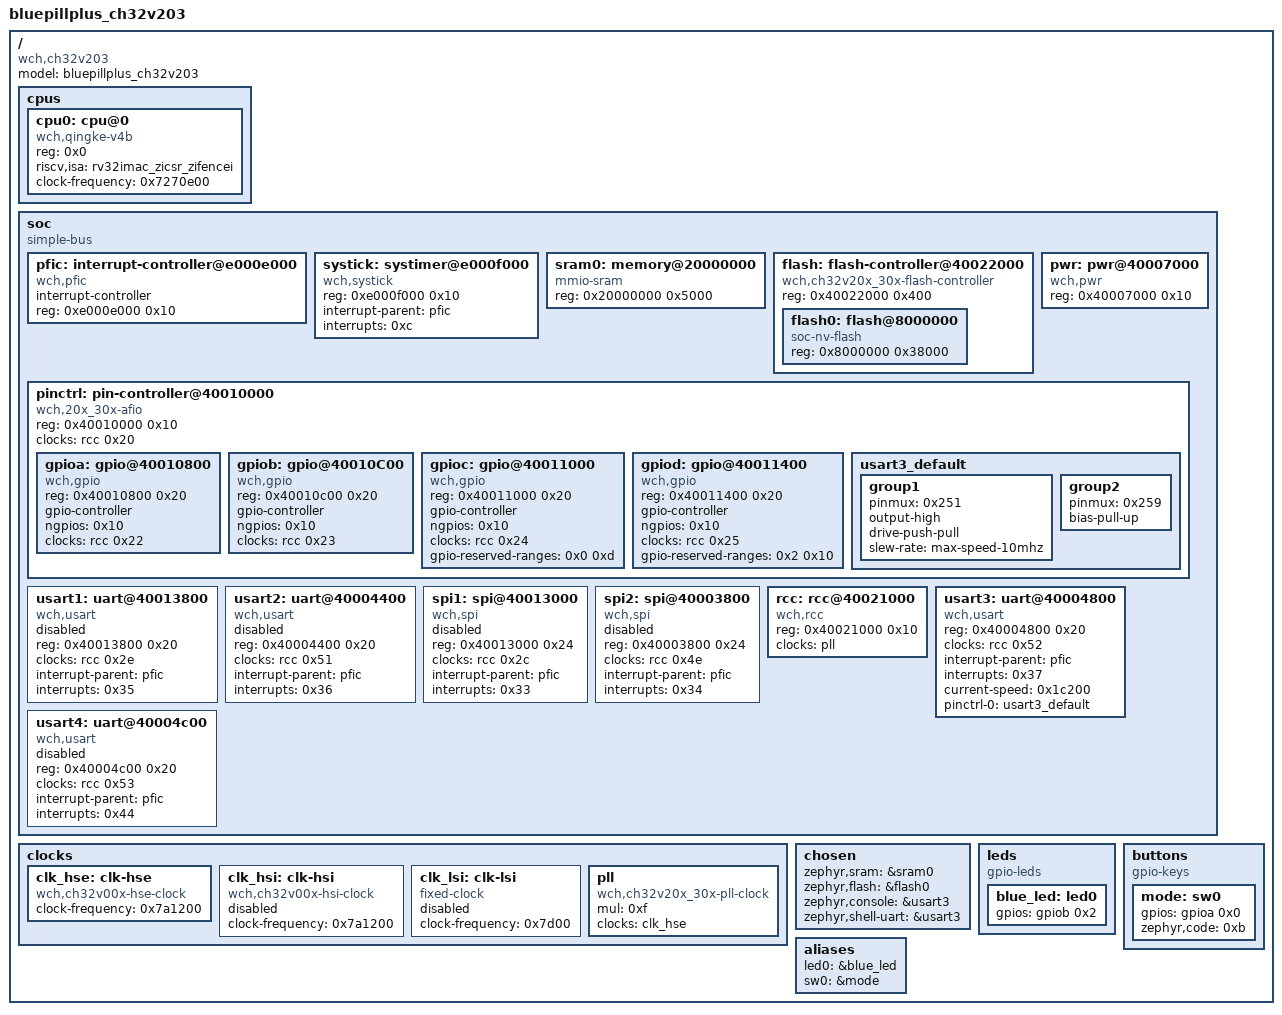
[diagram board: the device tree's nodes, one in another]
/dts-v1/;

/* node '/' defined in zephyr/dts/riscv/wch/qingke-v4b.dtsi:7 */
/ {
	#address-cells = < 0x1 >;        /* in zephyr/dts/riscv/wch/qingke-v4b.dtsi:8 */
	#size-cells = < 0x1 >;           /* in zephyr/dts/riscv/wch/qingke-v4b.dtsi:9 */
	model = "bluepillplus_ch32v203"; /* in zephyr/boards/weact/bluepillplus_ch32v203/bluepillplus_ch32v203.dts:14 */
	compatible = "wch,ch32v203";     /* in zephyr/boards/weact/bluepillplus_ch32v203/bluepillplus_ch32v203.dts:15 */

	/* node '/cpus' defined in zephyr/dts/riscv/wch/qingke-v4b.dtsi:11 */
	cpus {
		#address-cells = < 0x1 >; /* in zephyr/dts/riscv/wch/qingke-v4b.dtsi:12 */
		#size-cells = < 0x0 >;    /* in zephyr/dts/riscv/wch/qingke-v4b.dtsi:13 */

		/* node '/cpus/cpu@0' defined in zephyr/dts/riscv/wch/qingke-v4b.dtsi:15 */
		cpu0: cpu@0 {
			device_type = "cpu";                   /* in zephyr/dts/riscv/wch/qingke-v4b.dtsi:16 */
			compatible = "wch,qingke-v4b";         /* in zephyr/dts/riscv/wch/qingke-v4b.dtsi:17 */
			reg = < 0x0 >;                         /* in zephyr/dts/riscv/wch/qingke-v4b.dtsi:18 */
			riscv,isa = "rv32imac_zicsr_zifencei"; /* in zephyr/dts/riscv/wch/qingke-v4b.dtsi:19 */
			clock-frequency = < 0x7270e00 >;       /* in zephyr/dts/riscv/wch/ch32v203/ch32v203.dtsi:160 */
		};
	};

	/* node '/soc' defined in zephyr/dts/riscv/wch/qingke-v4b.dtsi:23 */
	soc {
		#address-cells = < 0x1 >;  /* in zephyr/dts/riscv/wch/qingke-v4b.dtsi:24 */
		#size-cells = < 0x1 >;     /* in zephyr/dts/riscv/wch/qingke-v4b.dtsi:25 */
		compatible = "simple-bus"; /* in zephyr/dts/riscv/wch/qingke-v4b.dtsi:26 */
		ranges;                    /* in zephyr/dts/riscv/wch/qingke-v4b.dtsi:27 */

		/* node '/soc/interrupt-controller@e000e000' defined in zephyr/dts/riscv/wch/qingke-v4b.dtsi:29 */
		pfic: interrupt-controller@e000e000 {
			compatible = "wch,pfic";    /* in zephyr/dts/riscv/wch/qingke-v4b.dtsi:30 */
			#address-cells = < 0x0 >;   /* in zephyr/dts/riscv/wch/qingke-v4b.dtsi:31 */
			#interrupt-cells = < 0x1 >; /* in zephyr/dts/riscv/wch/qingke-v4b.dtsi:32 */
			interrupt-controller;       /* in zephyr/dts/riscv/wch/qingke-v4b.dtsi:33 */
			reg = < 0xe000e000 0x10 >;  /* in zephyr/dts/riscv/wch/qingke-v4b.dtsi:34 */
			status = "okay";            /* in zephyr/dts/riscv/wch/qingke-v4b.dtsi:35 */
			phandle = < 0x1 >;          /* in zephyr/dts/riscv/wch/qingke-v4b.dtsi:42 */
		};

		/* node '/soc/systimer@e000f000' defined in zephyr/dts/riscv/wch/qingke-v4b.dtsi:38 */
		systick: systimer@e000f000 {
			compatible = "wch,systick";   /* in zephyr/dts/riscv/wch/qingke-v4b.dtsi:39 */
			reg = < 0xe000f000 0x10 >;    /* in zephyr/dts/riscv/wch/qingke-v4b.dtsi:40 */
			status = "okay";              /* in zephyr/dts/riscv/wch/qingke-v4b.dtsi:41 */
			interrupt-parent = < &pfic >; /* in zephyr/dts/riscv/wch/qingke-v4b.dtsi:42 */
			interrupts = < 0xc >;         /* in zephyr/dts/riscv/wch/qingke-v4b.dtsi:43 */
		};

		/* node '/soc/memory@20000000' defined in zephyr/dts/riscv/wch/ch32v203/ch32v203.dtsi:46 */
		sram0: memory@20000000 {
			compatible = "mmio-sram";    /* in zephyr/dts/riscv/wch/ch32v203/ch32v203.dtsi:47 */
			reg = < 0x20000000 0x5000 >; /* in zephyr/dts/riscv/wch/ch32v203/ch32v203c8t.dtsi:18 */
		};

		/* node '/soc/flash-controller@40022000' defined in zephyr/dts/riscv/wch/ch32v203/ch32v203.dtsi:50 */
		flash: flash-controller@40022000 {
			compatible = "wch,ch32v20x_30x-flash-controller"; /* in zephyr/dts/riscv/wch/ch32v203/ch32v203.dtsi:51 */
			reg = < 0x40022000 0x400 >;                       /* in zephyr/dts/riscv/wch/ch32v203/ch32v203.dtsi:52 */
			#address-cells = < 0x1 >;                         /* in zephyr/dts/riscv/wch/ch32v203/ch32v203.dtsi:53 */
			#size-cells = < 0x1 >;                            /* in zephyr/dts/riscv/wch/ch32v203/ch32v203.dtsi:54 */

			/* node '/soc/flash-controller@40022000/flash@8000000' defined in zephyr/dts/riscv/wch/ch32v203/ch32v203.dtsi:56 */
			flash0: flash@8000000 {
				compatible = "soc-nv-flash"; /* in zephyr/dts/riscv/wch/ch32v203/ch32v203.dtsi:57 */
				reg = < 0x8000000 0x38000 >; /* in zephyr/dts/riscv/wch/ch32v203/ch32v203.dtsi:58 */
			};
		};

		/* node '/soc/pwr@40007000' defined in zephyr/dts/riscv/wch/ch32v203/ch32v203.dtsi:62 */
		pwr: pwr@40007000 {
			compatible = "wch,pwr";    /* in zephyr/dts/riscv/wch/ch32v203/ch32v203.dtsi:63 */
			reg = < 0x40007000 0x10 >; /* in zephyr/dts/riscv/wch/ch32v203/ch32v203.dtsi:64 */
		};

		/* node '/soc/pin-controller@40010000' defined in zephyr/dts/riscv/wch/ch32v203/ch32v203.dtsi:67 */
		pinctrl: pin-controller@40010000 {
			compatible = "wch,20x_30x-afio"; /* in zephyr/dts/riscv/wch/ch32v203/ch32v203.dtsi:68 */
			reg = < 0x40010000 0x10 >;       /* in zephyr/dts/riscv/wch/ch32v203/ch32v203.dtsi:69 */
			#address-cells = < 0x1 >;        /* in zephyr/dts/riscv/wch/ch32v203/ch32v203.dtsi:70 */
			#size-cells = < 0x1 >;           /* in zephyr/dts/riscv/wch/ch32v203/ch32v203.dtsi:71 */
			clocks = < &rcc 0x20 >;          /* in zephyr/dts/riscv/wch/ch32v203/ch32v203.dtsi:72 */

			/* node '/soc/pin-controller@40010000/gpio@40010800' defined in zephyr/dts/riscv/wch/ch32v203/ch32v203.dtsi:74 */
			gpioa: gpio@40010800 {
				compatible = "wch,gpio";   /* in zephyr/dts/riscv/wch/ch32v203/ch32v203.dtsi:75 */
				reg = < 0x40010800 0x20 >; /* in zephyr/dts/riscv/wch/ch32v203/ch32v203.dtsi:76 */
				gpio-controller;           /* in zephyr/dts/riscv/wch/ch32v203/ch32v203.dtsi:77 */
				#gpio-cells = < 0x2 >;     /* in zephyr/dts/riscv/wch/ch32v203/ch32v203.dtsi:78 */
				ngpios = < 0x10 >;         /* in zephyr/dts/riscv/wch/ch32v203/ch32v203.dtsi:79 */
				clocks = < &rcc 0x22 >;    /* in zephyr/dts/riscv/wch/ch32v203/ch32v203.dtsi:80 */
				status = "okay";           /* in zephyr/boards/weact/bluepillplus_ch32v203/bluepillplus_ch32v203.dts:63 */
				phandle = < 0x7 >;         /* in zephyr/boards/weact/bluepillplus_ch32v203/bluepillplus_ch32v203.dts:37 */
			};

			/* node '/soc/pin-controller@40010000/gpio@40010C00' defined in zephyr/dts/riscv/wch/ch32v203/ch32v203.dtsi:83 */
			gpiob: gpio@40010C00 {
				compatible = "wch,gpio";   /* in zephyr/dts/riscv/wch/ch32v203/ch32v203.dtsi:84 */
				reg = < 0x40010c00 0x20 >; /* in zephyr/dts/riscv/wch/ch32v203/ch32v203.dtsi:85 */
				gpio-controller;           /* in zephyr/dts/riscv/wch/ch32v203/ch32v203.dtsi:86 */
				#gpio-cells = < 0x2 >;     /* in zephyr/dts/riscv/wch/ch32v203/ch32v203.dtsi:87 */
				ngpios = < 0x10 >;         /* in zephyr/dts/riscv/wch/ch32v203/ch32v203.dtsi:88 */
				clocks = < &rcc 0x23 >;    /* in zephyr/dts/riscv/wch/ch32v203/ch32v203.dtsi:89 */
				status = "okay";           /* in zephyr/boards/weact/bluepillplus_ch32v203/bluepillplus_ch32v203.dts:67 */
				phandle = < 0x6 >;         /* in zephyr/boards/weact/bluepillplus_ch32v203/bluepillplus_ch32v203.dts:29 */
			};

			/* node '/soc/pin-controller@40010000/gpio@40011000' defined in zephyr/dts/riscv/wch/ch32v203/ch32v203.dtsi:92 */
			gpioc: gpio@40011000 {
				compatible = "wch,gpio";            /* in zephyr/dts/riscv/wch/ch32v203/ch32v203.dtsi:93 */
				reg = < 0x40011000 0x20 >;          /* in zephyr/dts/riscv/wch/ch32v203/ch32v203.dtsi:94 */
				gpio-controller;                    /* in zephyr/dts/riscv/wch/ch32v203/ch32v203.dtsi:95 */
				#gpio-cells = < 0x2 >;              /* in zephyr/dts/riscv/wch/ch32v203/ch32v203.dtsi:96 */
				ngpios = < 0x10 >;                  /* in zephyr/dts/riscv/wch/ch32v203/ch32v203.dtsi:97 */
				clocks = < &rcc 0x24 >;             /* in zephyr/dts/riscv/wch/ch32v203/ch32v203.dtsi:98 */
				gpio-reserved-ranges = < 0x0 0xd >; /* in zephyr/dts/riscv/wch/ch32v203/ch32v203c8t.dtsi:10 */
				status = "okay";                    /* in zephyr/boards/weact/bluepillplus_ch32v203/bluepillplus_ch32v203.dts:71 */
			};

			/* node '/soc/pin-controller@40010000/gpio@40011400' defined in zephyr/dts/riscv/wch/ch32v203/ch32v203.dtsi:101 */
			gpiod: gpio@40011400 {
				compatible = "wch,gpio";             /* in zephyr/dts/riscv/wch/ch32v203/ch32v203.dtsi:102 */
				reg = < 0x40011400 0x20 >;           /* in zephyr/dts/riscv/wch/ch32v203/ch32v203.dtsi:103 */
				gpio-controller;                     /* in zephyr/dts/riscv/wch/ch32v203/ch32v203.dtsi:104 */
				#gpio-cells = < 0x2 >;               /* in zephyr/dts/riscv/wch/ch32v203/ch32v203.dtsi:105 */
				ngpios = < 0x10 >;                   /* in zephyr/dts/riscv/wch/ch32v203/ch32v203.dtsi:106 */
				clocks = < &rcc 0x25 >;              /* in zephyr/dts/riscv/wch/ch32v203/ch32v203.dtsi:107 */
				gpio-reserved-ranges = < 0x2 0x10 >; /* in zephyr/dts/riscv/wch/ch32v203/ch32v203c8t.dtsi:14 */
			};

			/* node '/soc/pin-controller@40010000/usart3_default' defined in zephyr/boards/weact/bluepillplus_ch32v203/bluepillplus_ch32v203-pinctrl.dtsi:9 */
			usart3_default: usart3_default {
				phandle = < 0x4 >; /* in zephyr/boards/weact/bluepillplus_ch32v203/bluepillplus_ch32v203.dts:77 */

				/* node '/soc/pin-controller@40010000/usart3_default/group1' defined in zephyr/boards/weact/bluepillplus_ch32v203/bluepillplus_ch32v203-pinctrl.dtsi:10 */
				group1 {
					pinmux = < 0x251 >;            /* in zephyr/boards/weact/bluepillplus_ch32v203/bluepillplus_ch32v203-pinctrl.dtsi:11 */
					output-high;                   /* in zephyr/boards/weact/bluepillplus_ch32v203/bluepillplus_ch32v203-pinctrl.dtsi:12 */
					drive-push-pull;               /* in zephyr/boards/weact/bluepillplus_ch32v203/bluepillplus_ch32v203-pinctrl.dtsi:13 */
					slew-rate = "max-speed-10mhz"; /* in zephyr/boards/weact/bluepillplus_ch32v203/bluepillplus_ch32v203-pinctrl.dtsi:14 */
				};

				/* node '/soc/pin-controller@40010000/usart3_default/group2' defined in zephyr/boards/weact/bluepillplus_ch32v203/bluepillplus_ch32v203-pinctrl.dtsi:17 */
				group2 {
					pinmux = < 0x259 >; /* in zephyr/boards/weact/bluepillplus_ch32v203/bluepillplus_ch32v203-pinctrl.dtsi:18 */
					bias-pull-up;       /* in zephyr/boards/weact/bluepillplus_ch32v203/bluepillplus_ch32v203-pinctrl.dtsi:19 */
				};
			};
		};

		/* node '/soc/uart@40013800' defined in zephyr/dts/riscv/wch/ch32v203/ch32v203.dtsi:111 */
		usart1: uart@40013800 {
			compatible = "wch,usart";     /* in zephyr/dts/riscv/wch/ch32v203/ch32v203.dtsi:112 */
			reg = < 0x40013800 0x20 >;    /* in zephyr/dts/riscv/wch/ch32v203/ch32v203.dtsi:113 */
			clocks = < &rcc 0x2e >;       /* in zephyr/dts/riscv/wch/ch32v203/ch32v203.dtsi:114 */
			interrupt-parent = < &pfic >; /* in zephyr/dts/riscv/wch/ch32v203/ch32v203.dtsi:115 */
			interrupts = < 0x35 >;        /* in zephyr/dts/riscv/wch/ch32v203/ch32v203.dtsi:116 */
			status = "disabled";          /* in zephyr/dts/riscv/wch/ch32v203/ch32v203.dtsi:117 */
		};

		/* node '/soc/uart@40004400' defined in zephyr/dts/riscv/wch/ch32v203/ch32v203.dtsi:120 */
		usart2: uart@40004400 {
			compatible = "wch,usart";     /* in zephyr/dts/riscv/wch/ch32v203/ch32v203.dtsi:121 */
			reg = < 0x40004400 0x20 >;    /* in zephyr/dts/riscv/wch/ch32v203/ch32v203.dtsi:122 */
			clocks = < &rcc 0x51 >;       /* in zephyr/dts/riscv/wch/ch32v203/ch32v203.dtsi:123 */
			interrupt-parent = < &pfic >; /* in zephyr/dts/riscv/wch/ch32v203/ch32v203.dtsi:124 */
			interrupts = < 0x36 >;        /* in zephyr/dts/riscv/wch/ch32v203/ch32v203.dtsi:125 */
			status = "disabled";          /* in zephyr/dts/riscv/wch/ch32v203/ch32v203.dtsi:126 */
		};

		/* node '/soc/spi@40013000' defined in zephyr/dts/riscv/wch/ch32v203/ch32v203.dtsi:129 */
		spi1: spi@40013000 {
			compatible = "wch,spi";       /* in zephyr/dts/riscv/wch/ch32v203/ch32v203.dtsi:130 */
			reg = < 0x40013000 0x24 >;    /* in zephyr/dts/riscv/wch/ch32v203/ch32v203.dtsi:131 */
			clocks = < &rcc 0x2c >;       /* in zephyr/dts/riscv/wch/ch32v203/ch32v203.dtsi:132 */
			interrupt-parent = < &pfic >; /* in zephyr/dts/riscv/wch/ch32v203/ch32v203.dtsi:133 */
			interrupts = < 0x33 >;        /* in zephyr/dts/riscv/wch/ch32v203/ch32v203.dtsi:134 */
			status = "disabled";          /* in zephyr/dts/riscv/wch/ch32v203/ch32v203.dtsi:135 */
			#address-cells = < 0x1 >;     /* in zephyr/dts/riscv/wch/ch32v203/ch32v203.dtsi:136 */
			#size-cells = < 0x0 >;        /* in zephyr/dts/riscv/wch/ch32v203/ch32v203.dtsi:137 */
		};

		/* node '/soc/spi@40003800' defined in zephyr/dts/riscv/wch/ch32v203/ch32v203.dtsi:140 */
		spi2: spi@40003800 {
			compatible = "wch,spi";       /* in zephyr/dts/riscv/wch/ch32v203/ch32v203.dtsi:141 */
			reg = < 0x40003800 0x24 >;    /* in zephyr/dts/riscv/wch/ch32v203/ch32v203.dtsi:142 */
			clocks = < &rcc 0x4e >;       /* in zephyr/dts/riscv/wch/ch32v203/ch32v203.dtsi:143 */
			interrupt-parent = < &pfic >; /* in zephyr/dts/riscv/wch/ch32v203/ch32v203.dtsi:144 */
			interrupts = < 0x34 >;        /* in zephyr/dts/riscv/wch/ch32v203/ch32v203.dtsi:145 */
			status = "disabled";          /* in zephyr/dts/riscv/wch/ch32v203/ch32v203.dtsi:146 */
			#address-cells = < 0x1 >;     /* in zephyr/dts/riscv/wch/ch32v203/ch32v203.dtsi:147 */
			#size-cells = < 0x0 >;        /* in zephyr/dts/riscv/wch/ch32v203/ch32v203.dtsi:148 */
		};

		/* node '/soc/rcc@40021000' defined in zephyr/dts/riscv/wch/ch32v203/ch32v203.dtsi:151 */
		rcc: rcc@40021000 {
			compatible = "wch,rcc";    /* in zephyr/dts/riscv/wch/ch32v203/ch32v203.dtsi:152 */
			reg = < 0x40021000 0x10 >; /* in zephyr/dts/riscv/wch/ch32v203/ch32v203.dtsi:153 */
			#clock-cells = < 0x1 >;    /* in zephyr/dts/riscv/wch/ch32v203/ch32v203.dtsi:154 */
			clocks = < &pll >;         /* in zephyr/boards/weact/bluepillplus_ch32v203/bluepillplus_ch32v203.dts:59 */
			phandle = < 0x2 >;         /* in zephyr/dts/riscv/wch/ch32v203/ch32v203.dtsi:72 */
		};

		/* node '/soc/uart@40004800' defined in zephyr/dts/riscv/wch/ch32v203/ch32v203c8t.dtsi:23 */
		usart3: uart@40004800 {
			compatible = "wch,usart";        /* in zephyr/dts/riscv/wch/ch32v203/ch32v203c8t.dtsi:24 */
			reg = < 0x40004800 0x20 >;       /* in zephyr/dts/riscv/wch/ch32v203/ch32v203c8t.dtsi:25 */
			clocks = < &rcc 0x52 >;          /* in zephyr/dts/riscv/wch/ch32v203/ch32v203c8t.dtsi:26 */
			interrupt-parent = < &pfic >;    /* in zephyr/dts/riscv/wch/ch32v203/ch32v203c8t.dtsi:27 */
			interrupts = < 0x37 >;           /* in zephyr/dts/riscv/wch/ch32v203/ch32v203c8t.dtsi:28 */
			status = "okay";                 /* in zephyr/boards/weact/bluepillplus_ch32v203/bluepillplus_ch32v203.dts:75 */
			current-speed = < 0x1c200 >;     /* in zephyr/boards/weact/bluepillplus_ch32v203/bluepillplus_ch32v203.dts:76 */
			pinctrl-0 = < &usart3_default >; /* in zephyr/boards/weact/bluepillplus_ch32v203/bluepillplus_ch32v203.dts:77 */
			pinctrl-names = "default";       /* in zephyr/boards/weact/bluepillplus_ch32v203/bluepillplus_ch32v203.dts:78 */
		};

		/* node '/soc/uart@40004c00' defined in zephyr/dts/riscv/wch/ch32v203/ch32v203c8t.dtsi:32 */
		usart4: uart@40004c00 {
			compatible = "wch,usart";     /* in zephyr/dts/riscv/wch/ch32v203/ch32v203c8t.dtsi:33 */
			reg = < 0x40004c00 0x20 >;    /* in zephyr/dts/riscv/wch/ch32v203/ch32v203c8t.dtsi:34 */
			clocks = < &rcc 0x53 >;       /* in zephyr/dts/riscv/wch/ch32v203/ch32v203c8t.dtsi:35 */
			interrupt-parent = < &pfic >; /* in zephyr/dts/riscv/wch/ch32v203/ch32v203c8t.dtsi:36 */
			interrupts = < 0x44 >;        /* in zephyr/dts/riscv/wch/ch32v203/ch32v203c8t.dtsi:37 */
			status = "disabled";          /* in zephyr/dts/riscv/wch/ch32v203/ch32v203c8t.dtsi:38 */
		};
	};

	/* node '/clocks' defined in zephyr/dts/riscv/wch/ch32v203/ch32v203.dtsi:15 */
	clocks {

		/* node '/clocks/clk-hse' defined in zephyr/dts/riscv/wch/ch32v203/ch32v203.dtsi:16 */
		clk_hse: clk-hse {
			#clock-cells = < 0x0 >;                /* in zephyr/dts/riscv/wch/ch32v203/ch32v203.dtsi:17 */
			compatible = "wch,ch32v00x-hse-clock"; /* in zephyr/dts/riscv/wch/ch32v203/ch32v203.dtsi:18 */
			clock-frequency = < 0x7a1200 >;        /* in zephyr/boards/weact/bluepillplus_ch32v203/bluepillplus_ch32v203.dts:49 */
			status = "okay";                       /* in zephyr/boards/weact/bluepillplus_ch32v203/bluepillplus_ch32v203.dts:50 */
			phandle = < 0x5 >;                     /* in zephyr/boards/weact/bluepillplus_ch32v203/bluepillplus_ch32v203.dts:54 */
		};

		/* node '/clocks/clk-hsi' defined in zephyr/dts/riscv/wch/ch32v203/ch32v203.dtsi:23 */
		clk_hsi: clk-hsi {
			#clock-cells = < 0x0 >;                /* in zephyr/dts/riscv/wch/ch32v203/ch32v203.dtsi:24 */
			compatible = "wch,ch32v00x-hsi-clock"; /* in zephyr/dts/riscv/wch/ch32v203/ch32v203.dtsi:25 */
			clock-frequency = < 0x7a1200 >;        /* in zephyr/dts/riscv/wch/ch32v203/ch32v203.dtsi:26 */
			status = "disabled";                   /* in zephyr/dts/riscv/wch/ch32v203/ch32v203.dtsi:27 */
		};

		/* node '/clocks/clk-lsi' defined in zephyr/dts/riscv/wch/ch32v203/ch32v203.dtsi:30 */
		clk_lsi: clk-lsi {
			#clock-cells = < 0x0 >;       /* in zephyr/dts/riscv/wch/ch32v203/ch32v203.dtsi:31 */
			compatible = "fixed-clock";   /* in zephyr/dts/riscv/wch/ch32v203/ch32v203.dtsi:32 */
			clock-frequency = < 0x7d00 >; /* in zephyr/dts/riscv/wch/ch32v203/ch32v203.dtsi:33 */
			status = "disabled";          /* in zephyr/dts/riscv/wch/ch32v203/ch32v203.dtsi:34 */
		};

		/* node '/clocks/pll' defined in zephyr/dts/riscv/wch/ch32v203/ch32v203.dtsi:37 */
		pll: pll {
			#clock-cells = < 0x0 >;                    /* in zephyr/dts/riscv/wch/ch32v203/ch32v203.dtsi:38 */
			compatible = "wch,ch32v20x_30x-pll-clock"; /* in zephyr/dts/riscv/wch/ch32v203/ch32v203.dtsi:39 */
			mul = < 0xf >;                             /* in zephyr/dts/riscv/wch/ch32v203/ch32v203.dtsi:40 */
			clocks = < &clk_hse >;                     /* in zephyr/boards/weact/bluepillplus_ch32v203/bluepillplus_ch32v203.dts:54 */
			status = "okay";                           /* in zephyr/boards/weact/bluepillplus_ch32v203/bluepillplus_ch32v203.dts:55 */
			phandle = < 0x3 >;                         /* in zephyr/boards/weact/bluepillplus_ch32v203/bluepillplus_ch32v203.dts:59 */
		};
	};

	/* node '/chosen' defined in zephyr/boards/weact/bluepillplus_ch32v203/bluepillplus_ch32v203.dts:17 */
	chosen {
		zephyr,sram = &sram0;        /* in zephyr/boards/weact/bluepillplus_ch32v203/bluepillplus_ch32v203.dts:18 */
		zephyr,flash = &flash0;      /* in zephyr/boards/weact/bluepillplus_ch32v203/bluepillplus_ch32v203.dts:19 */
		zephyr,console = &usart3;    /* in zephyr/boards/weact/bluepillplus_ch32v203/bluepillplus_ch32v203.dts:20 */
		zephyr,shell-uart = &usart3; /* in zephyr/boards/weact/bluepillplus_ch32v203/bluepillplus_ch32v203.dts:21 */
	};

	/* node '/leds' defined in zephyr/boards/weact/bluepillplus_ch32v203/bluepillplus_ch32v203.dts:24 */
	leds {
		compatible = "gpio-leds"; /* in zephyr/boards/weact/bluepillplus_ch32v203/bluepillplus_ch32v203.dts:25 */
		status = "okay";          /* in zephyr/boards/weact/bluepillplus_ch32v203/bluepillplus_ch32v203.dts:26 */

		/* node '/leds/led0' defined in zephyr/boards/weact/bluepillplus_ch32v203/bluepillplus_ch32v203.dts:28 */
		blue_led: led0 {
			gpios = < &gpiob 0x2 0x0 >; /* in zephyr/boards/weact/bluepillplus_ch32v203/bluepillplus_ch32v203.dts:29 */
		};
	};

	/* node '/buttons' defined in zephyr/boards/weact/bluepillplus_ch32v203/bluepillplus_ch32v203.dts:33 */
	buttons {
		compatible = "gpio-keys"; /* in zephyr/boards/weact/bluepillplus_ch32v203/bluepillplus_ch32v203.dts:34 */

		/* node '/buttons/sw0' defined in zephyr/boards/weact/bluepillplus_ch32v203/bluepillplus_ch32v203.dts:36 */
		mode: sw0 {
			gpios = < &gpioa 0x0 0x0 >; /* in zephyr/boards/weact/bluepillplus_ch32v203/bluepillplus_ch32v203.dts:37 */
			zephyr,code = < 0xb >;      /* in zephyr/boards/weact/bluepillplus_ch32v203/bluepillplus_ch32v203.dts:38 */
		};
	};

	/* node '/aliases' defined in zephyr/boards/weact/bluepillplus_ch32v203/bluepillplus_ch32v203.dts:42 */
	aliases {
		led0 = &blue_led; /* in zephyr/boards/weact/bluepillplus_ch32v203/bluepillplus_ch32v203.dts:43 */
		sw0 = &mode;      /* in zephyr/boards/weact/bluepillplus_ch32v203/bluepillplus_ch32v203.dts:44 */
	};
};
